# R7KA8M2AD register map
Vendor: Renesas Electronics Corporation; Series: RA8; File version: 1.10.02
CPU: CM85 r0p2, little endian, MPU, FPU, VTOR, 4 interrupt priority bits, 96 interrupts
Registers are 32-bit, read-write, reset 0x0 unless marked. A register's access mark holds for its fields unless they carry their own. Offsets are from the block's base; [hi:lo] are bit positions; {n}, {i} and the like mark numbered series; 'fields as' and 'values as' point back to an identical list.

## SRAM_NS — SRAM Control
Base 0x50002000
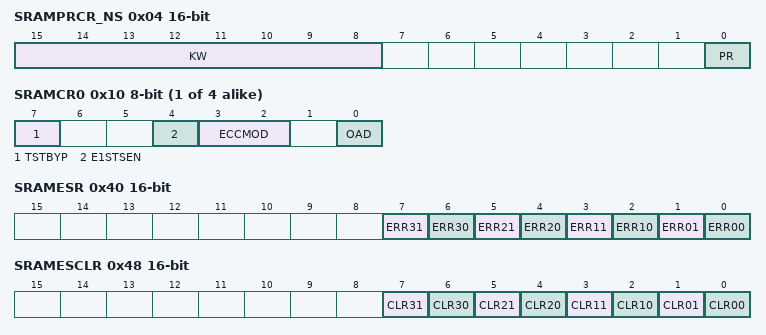
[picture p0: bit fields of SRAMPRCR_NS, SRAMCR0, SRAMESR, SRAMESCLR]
0x04 SRAMPRCR_NS 16-bit — SRAM Protection Control Register for Non-Secure
  [15:8] KW wo — Write Key Code
  [0] PR — Register Write Control
    0=Writing to registers are disabled; 1=Writing to registers are enabled
0x08 SRAMWTSC 8-bit — SRAM Wait State Control Register
  [0] WTEN — SRAM wait enable
    0=Do not add wait state in the access cycle to SRAMs; 1=Add wait state in the access cycle to SRAMs
{0x10+4i} SRAMCR{i} (i=0..3) 8-bit — SRAM Control Register {i} For ECC RAM
  [7] TSTBYP — ECC Test Enable / ECC Bypass Select
    0=Disable ECC bypass; 1=Enable ECC bypass
  [4] E1STSEN — ECC 1-bit Error Update Enable
    0=Disable updating of 1-bit ECC error; 1=Enable updating of 1-bit ECC error
  [3:2] ECCMOD — ECC Operating Mode Select
    0=Disable ECC function; 1=Setting prohibited; 2=Enable ECC function without error checking; 3=Enable ECC function with error checking
  [0] OAD — Operation after error detection
    0=Interrupt; 1=Reset
{0x30+4i} SRAMECCRGN{i} 8-bit reset 0x4 (i=0..2) — SRAM ECC Region Control Register {i}
  [2:0] ECCRGN — ECC target region select
    0=No ECC target region; 1={0x2200+8i}_0000–{0x2201+8i}_FFFF {0x3200+8i}_0000–{0x3201+8i}_FFFF (128 KB); 2={0x2200+8i}_0000–{0x2203+8i}_FFFF {0x3200+8i}_0000–{0x3203+8i}_FFFF (256 KB); 3={0x2200+8i}_0000–{0x2205+8i}_FFFF {0x3200+8i}_0000–{0x3205+8i}_FFFF (384 KB); 4={0x2200+8i}_0000–{0x2207+8i}_FFFF {0x3200+8i}_0000–{0x3207+8i}_FFFF (512 KB); other=Others (Setting prohibited)
0x3C SRAMECCRGN3 8-bit reset 0x1 — SRAM ECC Region Control Register 3
  [2:0] ECCRGN — ECC target region select
    0=No ECC target region; 1=0x2218_0000–0x2219_FFFF 0x3218_0000–0x3219_FFFF (128 KB); other=Others (Setting prohibited)
0x40 SRAMESR 16-bit ro — SRAM Error Status Register For ECC RAM
  [7] ERR31 — SRAM3 2-bit ECC Error Status
    0=2-bit ECC error has not occurred; 1=2-bit ECC error has occurred
  [6] ERR30 — SRAM3 1-bit ECC Error Status
    0=1-bit ECC error has not occurred; 1=1-bit ECC error has occurred
  [5] ERR21 — SRAM2 2-bit ECC Error Status
    values as ERR31
  [4] ERR20 — SRAM2 1-bit ECC Error Status
    values as ERR30
  [3] ERR11 — SRAM1 2-bit ECC Error Status
    values as ERR31
  [2] ERR10 — SRAM1 1-bit ECC Error Status
    values as ERR30
  [1] ERR01 — SRAM0 2-bit ECC Error Status
    values as ERR31
  [0] ERR00 — SRAM0 1-bit ECC Error Status
    values as ERR30
0x48 SRAMESCLR 16-bit wo — SRAM Error Status Clear Register For ECC RAM
  [7] CLR31 — SRAM3 2-bit ECC Error Status Clear
    0=No effect; 1=Clear 2-bit ECC error
  [6] CLR30 — SRAM3 1-bit ECC Error Status Clear
    0=No effect; 1=Clear 1-bit ECC error
  [5] CLR21 — SRAM2 2-bit ECC Error Status Clear
    0=No effect; 1=Clear 2-bit ECC error
  [4] CLR20 — SRAM2 1-bit ECC Error Status Clear
    0=No effect; 1=Clear 1-bit ECC error
  [3] CLR11 — SRAM1 2-bit ECC Error Status Clear
    0=No effect; 1=Clear 2-bit ECC error
  [2] CLR10 — SRAM1 1-bit ECC Error Status Clear
    0=No effect; 1=Clear 1-bit ECC error
  [1] CLR01 — SRAM0 2-bit ECC Error Status Clear
    0=No effect; 1=Clear 2-bit ECC error
  [0] CLR00 — SRAM0 1-bit ECC Error Status Clear
    0=No effect; 1=Clear 1-bit ECC error
{0x50+0x10*i} SRAMEAR{i}0 (i=0..3) ro — SRAM Error Address Register n0 For ECC RAM
{0x54+0x10*i} SRAMEAR{i}1 (i=0..3) ro — SRAM Error Address Register n1 For ECC RAM

## FCACHE_NS — SYSTEM/FLASH
Base 0x5001C100
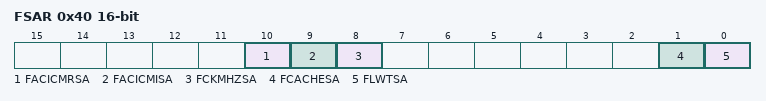
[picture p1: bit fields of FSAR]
0x40 FSAR 16-bit — Flash Security Attribution Register
  [all] fields
    0=Secure; 1=Non-secure
  [10] FACICMRSA — FACI command Registers Security Attribution
  [9] FACICMISA — FACI command Issuing Security Attribution
  [8] FCKMHZSA — FCKMHZ Security Attribution
  [1] FCACHESA — FCHACHEEN Security Attribution
  [0] FLWTSA — FLWT Security Attribution
